# CPU_DWT register map
Vendor: Texas Instruments
Peripheral module from a debugger description file (folder CC26x4).
Registers are 32-bit, read-only, reset 0x0 unless marked. A register's access mark holds for its fields unless they carry their own. Offsets are as the file gives them; lines under a group give offsets from that group; [hi:lo] are bit positions; {n}, {i} and the like mark numbered series; 'fields as' and 'values as' point back to an identical list; <NAME> marks a mode.

## CPU_DWT — Cortex-M's Data watchpoint and Trace (DWT)
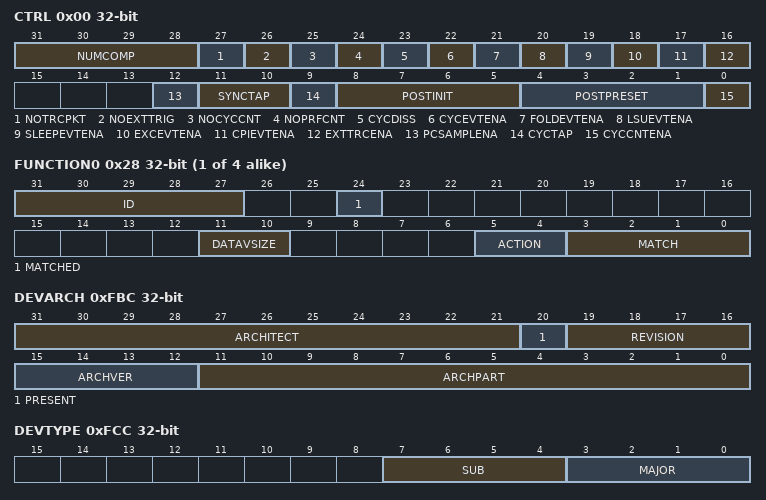
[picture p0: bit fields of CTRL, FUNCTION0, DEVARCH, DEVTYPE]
0x00 CTRL — Provides configuration and status information for the DWT unit, and used to control features of the unit
  [31:28] NUMCOMP — Number of DWT comparators implemented
  [27] NOTRCPKT — Indicates whether the implementation does not support trace
  [26] NOEXTTRIG — Reserved, RAZ
  [25] NOCYCCNT — Indicates whether the implementation does not include a cycle counter
  [24] NOPRFCNT — Indicates whether the implementation does not include the profiling counters
  [23] CYCDISS — Controls whether the cycle counter is disabled in Secure state
  [22] CYCEVTENA — Enables Event Counter packet generation on POSTCNT underflow
  [21] FOLDEVTENA — Enables DWT_FOLDCNT counter
  [20] LSUEVTENA — Enables DWT_LSUCNT counter
  [19] SLEEPEVTENA — Enable DWT_SLEEPCNT counter
  [18] EXCEVTENA — Enables DWT_EXCCNT counter
  [17] CPIEVTENA — Enables DWT_CPICNT counter
  [16] EXTTRCENA — Enables generation of Exception Trace packets
  [12] PCSAMPLENA — Enables use of POSTCNT counter as a timer for Periodic PC Sample packet generation
  [11:10] SYNCTAP — Selects the position of the synchronization packet counter tap on the CYCCNT counter. This determines the Synchronization packet rate
  [9] CYCTAP — Selects the position of the POSTCNT tap on the CYCCNT counter
  [8:5] POSTINIT — Initial value for the POSTCNT counter
  [4:1] POSTPRESET — Reload value for the POSTCNT counter
  [0] CYCCNTENA — Enables CYCCNT
0x04 CYCCNT rw — Shows or sets the value of the processor cycle counter, CYCCNT
  [31:0] CYCCNT — Increments one on each processor clock cycle when DWT_CTRL.CYCCNTENA == 1 and DEMCR.TRCENA == 1. On overflow, CYCCNT wraps to zero
0x08 CPICNT access per field — CPI Count Register
  [7:0] CPICNT rw — Counts one on each cycle when all of the following are true: - DWT_CTRL.CPIEVTENA == 1 and DEMCR.TRCENA == 1. - No instruction is executed. - No load-store operation is in progress, see DWT_LSUCNT. - No exception-entry or exception-exit operation is in progress, see DWT_EXCCNT. - The PE is not in a power saving mode, see DWT_SLEEPCNT. - Either SecureNoninvasiveDebugAllowed() == TRUE, or the PE is in Non-secure state and NoninvasiveDebugAllowed() == TRUE.
0x0C EXCCNT access per field — Counts the total cycles spent in exception processing
  [7:0] EXCCNT rw — Counts one on each cycle when all of the following are true: - DWT_CTRL.EXCEVTENA == 1 and DEMCR.TRCENA == 1. - No instruction is executed, see DWT_CPICNT. - An exception-entry or exception-exit related operation is in progress. - Either SecureNoninvasiveDebugAllowed() == TRUE, or NS-Req for the operation is set to Non-secure and NoninvasiveDebugAllowed() == TRUE.
0x10 SLEEPCNT access per field — Sleep Count Register
  [7:0] SLEEPCNT rw — Counts one on each cycle when all of the following are true: - DWT_CTRL.SLEEPEVTENA == 1 and DEMCR.TRCENA == 1. - No instruction is executed, see DWT_CPICNT. - No load-store operation is in progress, see DWT_LSUCNT. - No exception-entry or exception-exit operation is in progress, see DWT_EXCCNT. - The PE is in a power saving mode. - Either SecureNoninvasiveDebugAllowed() == TRUE, or the PE is in Non-secure state and NoninvasiveDebugAllowed() == TRUE.
0x14 LSUCNT access per field — Increments on the additional cycles required to execute all load or store instructions
  [7:0] LSUCNT rw — Counts one on each cycle when all of the following are true: - DWT_CTRL.LSUEVTENA == 1 and DEMCR.TRCENA == 1. - No instruction is executed, see DWT_CPICNT. - No exception-entry or exception-exit operation is in progress, see DWT_EXCCNT. - A load-store operation is in progress. - Either SecureNoninvasiveDebugAllowed() == TRUE, or NS-Req for the operation is set to Non-secure and NoninvasiveDebugAllowed() == TRUE.
0x18 FOLDCNT access per field — Increments on the additional cycles required to execute all load or store instructions
  [7:0] FOLDCNT rw — Counts on each cycle when all of the following are true: - DWT_CTRL.FOLDEVTENA == 1 and DEMCR.TRCENA == 1. - At least two instructions are executed, see DWT_CPICNT. - Either SecureNoninvasiveDebugAllowed() == TRUE, or the PE is in Non-secure state and NoninvasiveDebugAllowed() == TRUE. The counter is incremented by the number of instructions executed, minus one
0x1C PCSR — Program Counter Sample Register
  [31:0] EIASAMPLE — The possible values of this field are: 0xFFFFFFFF One of the following is true: - The PE is halted in Debug state. - The Security Extension is implemented, the sampled instruction was executed in Secure state, and SecureNoninvasiveDebugAllowed() == FALSE. - NoninvasiveDebugAllowed() == FALSE. - DEMCR.TRCENA == 0. - The address of a recently-executed instruction is not available. Not 0xFFFFFFFF Instruction address of a recently executed instruction. Bit [0] of the sample instruction address is 0.
{0x20+0x10*i} COMP{i} access not given reset not defined (i=0..3) — Provides a reference value for use by watchpoint comparator {i}
{0x28+0x10*i} FUNCTION{i} access per field (i=0..3) — Controls the operation of watchpoint comparator {i}
  [31:27] ID ro — Identifies the capabilities for MATCH for comparator *n
  [24] MATCHED ro — Set to 1 when the comparator matches
  [11:10] DATAVSIZE rw — Defines the size of the object being watched for by Data Value and Data Address comparators
  [5:4] ACTION rw — Defines the action on a match. This field is ignored and the comparator generates no actions if it is disabled by MATCH
  [3:0] MATCH rw — Controls the type of match generated by this comparator
0xFBC DEVARCH — Provides CoreSight discovery information for the DWT
  [31:21] ARCHITECT — Defines the architect of the component. Bits [31:28] are the JEP106 continuation code (JEP106 bank ID, minus 1) and bits [27:21] are the JEP106 ID code.
  [20] PRESENT — Defines that the DEVARCH register is present
  [19:16] REVISION — Defines the architecture revision of the component
  [15:12] ARCHVER — Defines the architecture version of the component
  [11:0] ARCHPART — Defines the architecture of the component
0xFCC DEVTYPE — Provides CoreSight discovery information for the DWT
  [7:4] SUB — Component sub-type
  [3:0] MAJOR — Component major type
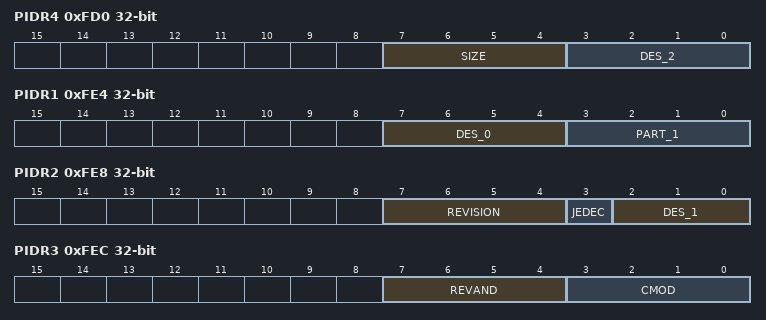
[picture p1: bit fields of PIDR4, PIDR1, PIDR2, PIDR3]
0xFD0 PIDR4 — Provides CoreSight discovery information for the DWT
  [7:4] SIZE — See CoreSight Architecture Specification
  [3:0] DES_2 — See CoreSight Architecture Specification
{0xFC0+4i} PIDR{i} (i=5..7) — Provides CoreSight discovery information for the DWT
0xFE0 PIDR0 — Provides CoreSight discovery information for the DWT
  [7:0] PART_0 — See CoreSight Architecture Specification
0xFE4 PIDR1 — Provides CoreSight discovery information for the DWT
  [7:4] DES_0 — See CoreSight Architecture Specification
  [3:0] PART_1 — See CoreSight Architecture Specification
0xFE8 PIDR2 — Provides CoreSight discovery information for the DWT
  [7:4] REVISION — See CoreSight Architecture Specification
  [3] JEDEC — See CoreSight Architecture Specification
  [2:0] DES_1 — See CoreSight Architecture Specification
0xFEC PIDR3 — Provides CoreSight discovery information for the DWT
  [7:4] REVAND — See CoreSight Architecture Specification
  [3:0] CMOD — See CoreSight Architecture Specification
0xFF0 CIDR0 — Provides CoreSight discovery information for the DWT
  [7:0] PRMBL_0 — See CoreSight Architecture Specification
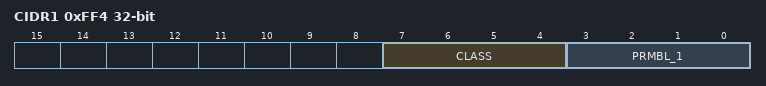
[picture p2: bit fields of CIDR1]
0xFF4 CIDR1 — Provides CoreSight discovery information for the DWT
  [7:4] CLASS — See CoreSight Architecture Specification
  [3:0] PRMBL_1 — See CoreSight Architecture Specification
0xFF8 CIDR2 — Provides CoreSight discovery information for the DWT
  [7:0] PRMBL_2 — See CoreSight Architecture Specification
0xFFC CIDR3 — Provides CoreSight discovery information for the DWT
  [7:0] PRMBL_3 — See CoreSight Architecture Specification
